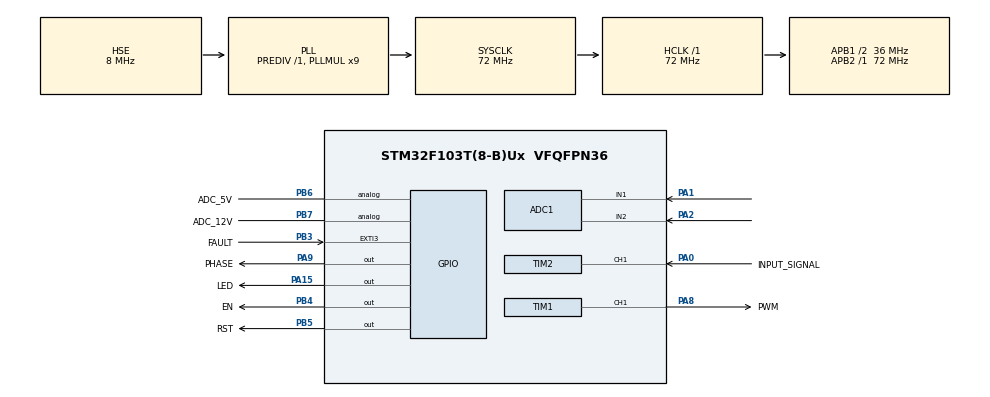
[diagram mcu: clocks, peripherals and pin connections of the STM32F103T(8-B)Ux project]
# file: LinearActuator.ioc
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ADC1.Channel-2\#ChannelRegularConversion=ADC_CHANNEL_1
ADC1.Channel-3\#ChannelRegularConversion=ADC_CHANNEL_2
ADC1.ContinuousConvMode=ENABLE
ADC1.NbrOfConversion=2
ADC1.NbrOfConversionFlag=1
ADC1.Rank-2\#ChannelRegularConversion=1
ADC1.Rank-3\#ChannelRegularConversion=2
ADC1.SamplingTime-2\#ChannelRegularConversion=ADC_SAMPLETIME_1CYCLE_5
ADC1.SamplingTime-3\#ChannelRegularConversion=ADC_SAMPLETIME_1CYCLE_5
ADC1.master=1
Dma.ADC1.0.Direction=DMA_PERIPH_TO_MEMORY
Dma.ADC1.0.Instance=DMA1_Channel1
Dma.ADC1.0.MemDataAlignment=DMA_MDATAALIGN_HALFWORD
Dma.ADC1.0.MemInc=DMA_MINC_ENABLE
Dma.ADC1.0.Mode=DMA_CIRCULAR
Dma.ADC1.0.PeriphDataAlignment=DMA_PDATAALIGN_HALFWORD
Dma.ADC1.0.PeriphInc=DMA_PINC_DISABLE
Dma.ADC1.0.Priority=DMA_PRIORITY_LOW
Dma.Request0=ADC1
Mcu.Family=STM32F1
Mcu.Name=STM32F103T(8-B)Ux
Mcu.Package=VFQFPN36
NVIC.ADC1_2_IRQn=true\:0\:0\:false\:false\:true\:true\:true
NVIC.DMA1_Channel1_IRQn=true\:0\:0\:false\:false\:true\:false\:true
NVIC.PriorityGroup=NVIC_PRIORITYGROUP_4
PA0-WKUP.GPIO_Label=INPUT_SIGNAL
PA0-WKUP.Signal=S_TIM2_CH1_ETR
PA1.Signal=ADCx_IN1
PA13.Mode=Serial_Wire
PA13.Signal=SYS_JTMS-SWDIO
PA14.Mode=Serial_Wire
PA14.Signal=SYS_JTCK-SWCLK
PA15.GPIO_Label=LED
PA15.Signal=GPIO_Output
PA2.Signal=ADCx_IN2
PA8.GPIO_Label=PWM
PA8.Signal=S_TIM1_CH1
PA9.GPIO_Label=PHASE
PA9.GPIO_Speed=GPIO_SPEED_FREQ_HIGH
PA9.Signal=GPIO_Output
PB3.GPIO_Label=FAULT
PB3.Signal=GPXTI3
PB4.GPIO_Label=EN
PB4.Signal=GPIO_Output
PB5.GPIO_Label=RST
PB5.Signal=GPIO_Output
PB6.GPIO_Label=ADC_5V
PB6.Signal=GPIO_Analog
PB7.GPIO_Label=ADC_12V
PB7.Signal=GPIO_Analog
PD0-OSC_IN.Mode=HSE-External-Oscillator
PD0-OSC_IN.Signal=RCC_OSC_IN
PD1-OSC_OUT.Mode=HSE-External-Oscillator
PD1-OSC_OUT.Signal=RCC_OSC_OUT
ProjectManager.HeapSize=0x200
ProjectManager.StackSize=0x400
ProjectManager.TargetToolchain=Makefile
RCC.ADCPresc=RCC_ADCPCLK2_DIV6
RCC.AHBFreq_Value=72000000
RCC.APB1CLKDivider=RCC_HCLK_DIV2
RCC.APB1Freq_Value=36000000
RCC.APB1TimFreq_Value=72000000
RCC.APB2Freq_Value=72000000
RCC.APB2TimFreq_Value=72000000
RCC.HCLKFreq_Value=72000000
RCC.LockedElements=AHBOutput
RCC.PLLMUL=RCC_PLL_MUL9
RCC.PLLSourceVirtual=RCC_PLLSOURCE_HSE
RCC.SYSCLKFreq_VALUE=72000000
RCC.SYSCLKSource=RCC_SYSCLKSOURCE_PLLCLK
RCC.USBFreq_Value=72000000
SH.ADCx_IN1.0=ADC2_IN1
SH.ADCx_IN1.1=ADC1_IN1,IN1
SH.ADCx_IN2.0=ADC2_IN2
SH.ADCx_IN2.1=ADC1_IN2,IN2
SH.S_TIM1_CH1.0=TIM1_CH1,PWM Generation1 CH1
SH.S_TIM2_CH1_ETR.0=TIM2_CH1,Input_Capture1_from_TI1
TIM1.Channel-PWM\ Generation1\ CH1=TIM_CHANNEL_1
TIM2.Channel-Input_Capture1_from_TI1=TIM_CHANNEL_1
VP_TIM1_VS_ClockSourceINT.Mode=Internal
board=custom

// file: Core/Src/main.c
/* USER CODE BEGIN Header */
/**
  ******************************************************************************
  * @file           : main.c
  * @brief          : Main program body
  ******************************************************************************
  * @attention
  *
  * <h2><center>&copy; Copyright (c) 2021 STMicroelectronics.
  * All rights reserved.</center></h2>
  *
  * This software component is licensed by ST under BSD 3-Clause license,
  * the "License"; You may not use this file except in compliance with the
  * License. You may obtain a copy of the License at:
  *                        opensource.org/licenses/BSD-3-Clause
  *
  ******************************************************************************
  */
/* USER CODE END Header */
#include "main.h"
#include "adc.h"
#include "dma.h"
#include "tim.h"
#include "gpio.h"

/* USER CODE BEGIN Includes */
#include "stdio.h"
int _write(int file, char *ptr, int len)
{
  /* Implement your write code here, this is used by puts and printf for example */
  int i=0;
  for(i=0 ; i<len ; i++)
    ITM_SendChar((*ptr++));
  return len;
}
/* USER CODE END Includes */

/* USER CODE BEGIN PV */
uint16_t sensor[2];
/* USER CODE END PV */

void SystemClock_Config(void);

int main(void)
{

  /* MCU Configuration--------------------------------------------------------*/

  /* Reset of all peripherals, Initializes the Flash interface and the Systick. */
  HAL_Init();

  /* Configure the system clock */
  SystemClock_Config();

  /* Initialize all configured peripherals */
  MX_GPIO_Init();
  MX_TIM1_Init();
  MX_TIM2_Init();
  MX_DMA_Init();
  MX_ADC1_Init();
  /* USER CODE BEGIN 2 */
  HAL_ADCEx_Calibration_Start(&hadc1);
  HAL_ADC_Start(&hadc1);
  HAL_ADC_Start_DMA(&hadc1,(uint32_t *)sensor,2);
  /* USER CODE END 2 */

  /* Infinite loop */
  /* USER CODE BEGIN WHILE */
  while (1)
  {
    HAL_GPIO_TogglePin(LED_GPIO_Port,LED_Pin);
    printf("Hello World\n");
    HAL_Delay(50);
    /* USER CODE END WHILE */

  }
}

void SystemClock_Config(void)
{
  RCC_OscInitTypeDef RCC_OscInitStruct = {0};
  RCC_ClkInitTypeDef RCC_ClkInitStruct = {0};
  RCC_PeriphCLKInitTypeDef PeriphClkInit = {0};

  /** Initializes the RCC Oscillators according to the specified parameters
  * in the RCC_OscInitTypeDef structure.
  */
  RCC_OscInitStruct.OscillatorType = RCC_OSCILLATORTYPE_HSE;
  RCC_OscInitStruct.HSEState = RCC_HSE_ON;
  RCC_OscInitStruct.HSEPredivValue = RCC_HSE_PREDIV_DIV1;
  RCC_OscInitStruct.HSIState = RCC_HSI_ON;
  RCC_OscInitStruct.PLL.PLLState = RCC_PLL_ON;
  RCC_OscInitStruct.PLL.PLLSource = RCC_PLLSOURCE_HSE;
  RCC_OscInitStruct.PLL.PLLMUL = RCC_PLL_MUL9;
  if (HAL_RCC_OscConfig(&RCC_OscInitStruct) != HAL_OK)
  {
    Error_Handler();
  }
  /** Initializes the CPU, AHB and APB buses clocks
  */
  RCC_ClkInitStruct.ClockType = RCC_CLOCKTYPE_HCLK|RCC_CLOCKTYPE_SYSCLK
                              |RCC_CLOCKTYPE_PCLK1|RCC_CLOCKTYPE_PCLK2;
  RCC_ClkInitStruct.SYSCLKSource = RCC_SYSCLKSOURCE_PLLCLK;
  RCC_ClkInitStruct.AHBCLKDivider = RCC_SYSCLK_DIV1;
  RCC_ClkInitStruct.APB1CLKDivider = RCC_HCLK_DIV2;
  RCC_ClkInitStruct.APB2CLKDivider = RCC_HCLK_DIV1;

  if (HAL_RCC_ClockConfig(&RCC_ClkInitStruct, FLASH_LATENCY_2) != HAL_OK)
  {
    Error_Handler();
  }
  PeriphClkInit.PeriphClockSelection = RCC_PERIPHCLK_ADC;
  PeriphClkInit.AdcClockSelection = RCC_ADCPCLK2_DIV6;
  if (HAL_RCCEx_PeriphCLKConfig(&PeriphClkInit) != HAL_OK)
  {
    Error_Handler();
  }
}

void Error_Handler(void)
{
  __disable_irq();
  while (1)
  {
  }
}

/************************ (C) COPYRIGHT STMicroelectronics *****END OF FILE****/
